# A33M11x register map
Vendor: ABOV Semiconductor Co., Ltd.; File version: 1.0
CPU: CM3 r0p1, little endian, MPU, FPU, VTOR, 4 interrupt priority bits
Registers are 32-bit, read-write, reset 0x0 unless marked. A register's access mark holds for its fields unless they carry their own. Offsets are from the block's base; [hi:lo] are bit positions; {n}, {i} and the like mark numbered series.

## SPI0 — Serial Peripheral Interface Bus
Base 0x40009000
Same registers: SPI1 0x40009100
0x00 TDR wo — SPI n Transmit Data Register
  [16:0] TDR — Transmit Data Bit
0x00 RDR ro — SPI n Received Data Register
  [16:0] RDR — Received Data Bit
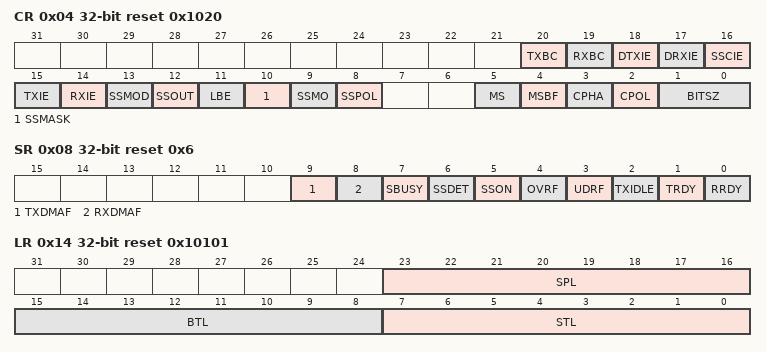
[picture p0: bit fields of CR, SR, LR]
0x04 CR reset 0x1020 — SPI Control Register
  [20] TXBC — Tx Buffer Clear Bit
  [19] RXBC — Rx Buffer Clear Bit
  [18] DTXIE — DMA Tx Complete Interrupt Enable Bit
  [17] DRXIE — DMA Rx Complete Interrupt Enable Bit
  [16] SSCIE — SS Edge Changed Interrupt Enable Bit
  [15] TXIE — Transmit Interrupt Enable Bit
  [14] RXIE — Received Interrupt Enable Bit
  [13] SSMOD — SS Auto/Manual Output Selection Bit in Master Mode
  [12] SSOUT — SS Output Signal Control Bit
  [11] LBE — Loop-back Mode Selection Bit in Master Mode
  [10] SSMASK — SS Signal Masking in Slave Mode
  [9] SSMO — SS Output Signal Selection Bit
  [8] SSPOL — SS Signal Polarity Selection Bit
  [5] MS — Master/Slave Selection Bit
  [4] MSBF — MSB/LSB Transmit Advance Selection Bit
  [3] CPHA — SPI Clock Phase Bit
  [2] CPOL — SPI Clock Polarity Bit
  [1:0] BITSZ — Transmit/Receive Bit Size Selection Bit
    0=8_BIT (Size is 8 bit); 1=9_BIT (Size is 9 bit); 2=16_BIT (Size is 16 bit); 3=17_BIT (Size is 17 bit)
0x08 SR reset 0x6 — SPI n Status Register
  [9] TXDMAF — DMA Transmit Operation Complete Flag
  [8] RXDMAF — DMA Received Operation Complete Flag
  [7] SBUSY ro — Transmit/Received Operating Flag
  [6] SSDET — SS Signal Rising or Falling Edge Detected Flag
  [5] SSON — SS Signal Status Flag
  [4] OVRF — Received Overrun Error Flag
  [3] UDRF — Transmit Underrun Error Flag
  [2] TXIDLE ro — Transmit Operating Flag
  [1] TRDY ro — Transmit Buffer Empty Flag
  [0] RRDY ro — Received Buffer Empty Flag
0x0C BR reset 0xFF — SPI n Baud Rate Register
  [15:0] BR — Baud Rate Setting Bit
0x10 EN — SPI n Enable Register
  [0] ENABLE — SPI Enable Bit
0x14 LR reset 0x10101 — SPI n Delay Length Register
  [23:16] SPL — SPI STOP Length Value Bit
  [15:8] BTL — SPI Burst Length Value Bit
  [7:0] STL — SPI Start Length Value Bit

## I2C0 — Inter-Integrated Circuit
Base 0x4000A000
Same registers: I2C1 0x4000A100
0x00 DR reset 0xFF — I2Cn Data Register
  [7:0] ICDR — The I2CnDR Transmit buffer and Receive buffer share the same I/O address with this DATA register. The Transmit Data Buffer is the destination for data written to the I2CnDR register. Reading the I2CnDR register returns the contents of the Receive Buffer.
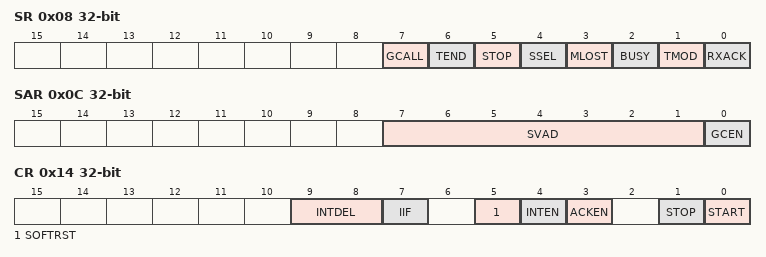
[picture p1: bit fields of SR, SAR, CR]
0x08 SR — I2Cn Status Register
  [7] GCALL — This bit has different meaning depending on whether I2C is master or slave. When I2C is a master, this bit represents whether it received AACK (address ACK) from slave.
  [6] TEND — This bit is set when 1-byte of data is transferred completely.
  [5] STOP — This bit is set when a STOP condition is detected.
  [4] SSEL — This bit is set when I2C is addressed by other master.
  [3] MLOST — This bit represents the result of bus arbitration in master mode.
  [2] BUSY — This bit reflects bus status.
  [1] TMOD ro — This bit is used to indicate whether I2C is transmitter or receiver.
  [0] RXACK — This bit shows the state of ACK signal.
0x0C SAR — I2Cn Slave Address Register
  [7:1] SVAD — These bits configure the slave address in slave mode.
  [0] GCEN — This bit decides whether I2Cn allows general call address 0 or not in I2Cn slave mode.
0x14 CR — I2Cn Control Register
  [9:8] INTDEL — between Address and Transmit data delay
    0=1_ICnSCLL (Delay = 1*ICnSCLL); 1=2_ICnSCLL (Delay = 2*ICnSCLL); 2=4_ICnSCLL (Delay = 4*ICnSCLL); 3=8_ICnSCLL (Delay = 8*ICnSCLL)
  [7] IIF ro — I2Cn Interrupt Flag bit. This bit is cleared when write any values in the I2CnST register.
  [5] SOFTRST — Software Reset allow bit
  [4] INTEN — Interrupt Enable bit
  [3] ACKEN — received mode ACK allow bit
  [1] STOP — STOP Condition Generation When I2Cn is master.
  [0] START — START Condition Generation When I2Cn is master.
0x18 SCLLLR reset 0xFFFF — I2Cn SCL Low Period Register
  [15:0] SCLL — This register defines the low period of SCL in master mode. The base clock is PCLK and the period is calculated by the formula: tPCLK X (4 X I2CnSCLR + 2) where tPCLK is the period of PCLK.
0x1C SCLHR reset 0xFFFF — I2Cn SCL High Period Register
  [15:0] SCLH — SCLH Value
0x20 SDAHR reset 0x7FFF — I2Cn SCL Hold Time Register
  [14:0] SDH — SDH Value

## AFE — Analog Front End
Base 0x4000B300
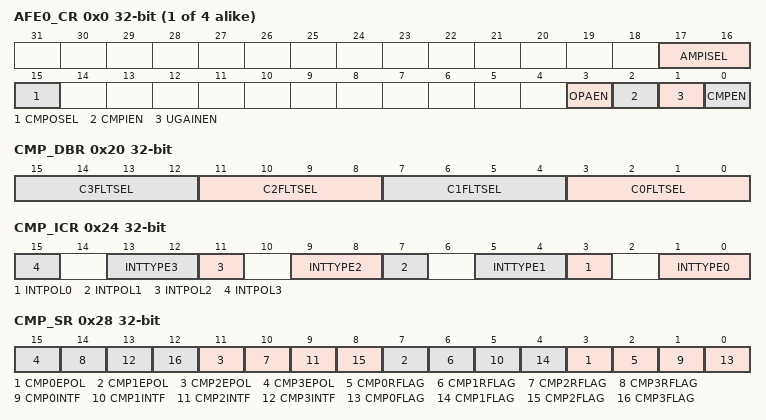
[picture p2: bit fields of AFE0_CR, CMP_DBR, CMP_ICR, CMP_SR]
{0x0+4i} AFE{i}_CR (i=0..3) — AFE Control Register
  [17:16] AMPISEL — OPAMP Current Setting Bit
  [15] CMPOSEL — Comparator Output Polarity Setting Bit
  [3] OPAEN — OPAMP Enable Bit
    0=Disable; 1=Enable
  [2] CMPIEN — Comparator Interrupt Enable Bit
    0=Disable; 1=Enable
  [1] UGAINEN — Unit Gain Enable Bit
    0=Disable; 1=Enable
  [0] CMPEN — Comparator Enable Bit
    0=Disable; 1=Enable
0x20 CMP_DBR — Comparator Debounce Register
  [4n+3:4n] C{n}FLTSEL (n=0..3) — Comparator {n} Filter Counter Selection Bit
0x24 CMP_ICR — Comparator Interrupt Control Register
  [4n+3] INTPOL{n} (n=0..3) — Comparator {n} Interrupt Polarity Selection Bit
  [4n+1:4n] INTTYPE{n} (n=0..3) — Comparator {n} Interrupt Type Selection Bit
0x28 CMP_SR — Comparator Status Register
  [4n+3] CMP{n}EPOL (n=0..3) — Comparator {n} Edge Polarity Status Bit
  [4n+2] CMP{n}RFLAG (n=0..3) — Comparator {n} Raw Flag Bit
  [4n+1] CMP{n}INTF (n=0..3) — Comparator {n} Interrupt Flag Bit
  [4n] CMP{n}FLAG (n=0..3) — Comparator {n} Output Flag Bit

## CRC — CYCLIC REDUNDANCY CHECK AND CHECKSUM
Base 0x41002000
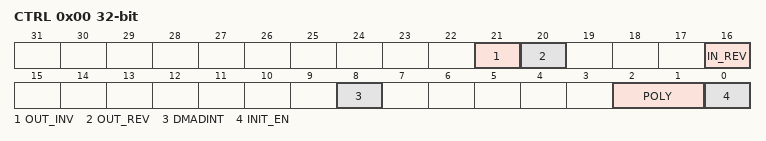
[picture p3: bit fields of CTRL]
0x00 CTRL — CRC Control Register
  [21] OUT_INV — CRC Output Data Inversion Enable bit
  [20] OUT_REV — CRC Output Data Reverse Enable Bit
  [16] IN_REV — Input Data Reverse Mode Selection Bit
  [8] DMADINT — DMA Done Interrupt Enable Bit
  [2:1] POLY — Polynomal Selection Bit
    0=CRC32 (0x04C1_1DB7); 1=CRC16 (0x8005); 2=CRC8 (0x07); 3=CRC7 (0x09)
  [0] INIT_EN wo — CRC Init Register Apply Bit
0x04 INIT — CRC Init value Register
  [31:0] INIT — CRC Initial Value
0x08 IDR wo — CRC Input Data Register
  [31:0] INPUT — CRC Input Data Bit
0x08 ODR ro — CRC Output Data Register
  [31:0] OUTPUT — CRC Output Data Bit
0x0C STAT — CRC Status Register
  [8] DMADINT — DMA Done Interrupt Flag Bit
